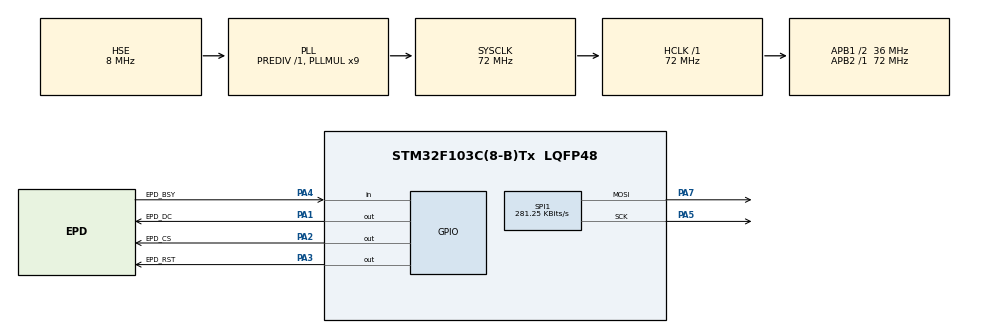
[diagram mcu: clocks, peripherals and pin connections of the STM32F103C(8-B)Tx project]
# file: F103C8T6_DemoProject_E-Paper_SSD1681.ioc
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Dma.Request0=SPI1_TX
Dma.SPI1_TX.0.Direction=DMA_MEMORY_TO_PERIPH
Dma.SPI1_TX.0.Instance=DMA1_Channel3
Dma.SPI1_TX.0.MemDataAlignment=DMA_MDATAALIGN_BYTE
Dma.SPI1_TX.0.MemInc=DMA_MINC_ENABLE
Dma.SPI1_TX.0.Mode=DMA_NORMAL
Dma.SPI1_TX.0.PeriphDataAlignment=DMA_PDATAALIGN_BYTE
Dma.SPI1_TX.0.PeriphInc=DMA_PINC_DISABLE
Dma.SPI1_TX.0.Priority=DMA_PRIORITY_LOW
Mcu.Family=STM32F1
Mcu.Name=STM32F103C(8-B)Tx
Mcu.Package=LQFP48
NVIC.DMA1_Channel3_IRQn=true\:0\:0\:false\:false\:true\:false\:true\:true
NVIC.PriorityGroup=NVIC_PRIORITYGROUP_4
NVIC.SPI1_IRQn=true\:0\:0\:false\:false\:true\:true\:true\:true
PA1.GPIO_Label=EPD_DC
PA1.Signal=GPIO_Output
PA13.Mode=Serial_Wire
PA13.Signal=SYS_JTMS-SWDIO
PA14.Mode=Serial_Wire
PA14.Signal=SYS_JTCK-SWCLK
PA2.GPIO_Label=EPD_CS
PA2.Signal=GPIO_Output
PA3.GPIO_Label=EPD_RST
PA3.Signal=GPIO_Output
PA4.GPIO_Label=EPD_BSY
PA4.Signal=GPIO_Input
PA5.Mode=TX_Only_Simplex_Unidirect_Master
PA5.Signal=SPI1_SCK
PA7.Mode=TX_Only_Simplex_Unidirect_Master
PA7.Signal=SPI1_MOSI
PD0-OSC_IN.Mode=HSE-External-Oscillator
PD0-OSC_IN.Signal=RCC_OSC_IN
PD1-OSC_OUT.Mode=HSE-External-Oscillator
PD1-OSC_OUT.Signal=RCC_OSC_OUT
ProjectManager.HeapSize=0x200
ProjectManager.StackSize=0x400
ProjectManager.TargetToolchain=STM32CubeIDE
RCC.AHBFreq_Value=72000000
RCC.APB1CLKDivider=RCC_HCLK_DIV2
RCC.APB1Freq_Value=36000000
RCC.APB1TimFreq_Value=72000000
RCC.APB2Freq_Value=72000000
RCC.APB2TimFreq_Value=72000000
RCC.HCLKFreq_Value=72000000
RCC.PLLMUL=RCC_PLL_MUL9
RCC.PLLSourceVirtual=RCC_PLLSOURCE_HSE
RCC.SYSCLKFreq_VALUE=72000000
RCC.SYSCLKSource=RCC_SYSCLKSOURCE_PLLCLK
RCC.USBFreq_Value=72000000
SPI1.BaudRatePrescaler=SPI_BAUDRATEPRESCALER_256
SPI1.CLKPhase=SPI_PHASE_1EDGE
SPI1.CLKPolarity=SPI_POLARITY_LOW
SPI1.CalculateBaudRate=281.25 KBits/s
SPI1.Direction=SPI_DIRECTION_2LINES
SPI1.Mode=SPI_MODE_MASTER
SPI1.VirtualType=VM_MASTER
board=custom

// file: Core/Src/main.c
/* USER CODE BEGIN Header */
/**
  ******************************************************************************
  * @file           : main.c
  * @brief          : Main program body
  ******************************************************************************
  * @attention
  *
  * Copyright (c) 2024 STMicroelectronics.
  * All rights reserved.
  *
  * This software is licensed under terms that can be found in the LICENSE file
  * in the root directory of this software component.
  * If no LICENSE file comes with this software, it is provided AS-IS.
  *
  ******************************************************************************
  */
/* USER CODE END Header */
#include "main.h"
#include "EPD_1-54inch.h"

SPI_HandleTypeDef hspi1;
DMA_HandleTypeDef hdma_spi1_tx;

/* USER CODE BEGIN PV */
EPD_StructTd Display;
/* USER CODE END PV */

void SystemClock_Config(void);
static void MX_GPIO_Init(void);
static void MX_DMA_Init(void);
static void MX_SPI1_Init(void);

/* USER CODE BEGIN 0 */
uint8_t mdw_Logo[] = {
		0xFF, 0xFF, 0xFF, 0xFF, 0xFF, 0xFF, 0xFF, 0xFF, 0xFF, 0xFF, 0xFF, 0xFF, 0xFF, 0xFF, 0xFF, 0xFF,
		0xFF, 0xFF, 0xFF, 0xFF, 0xFF, 0xFF, 0xFF, 0xFF, 0xFF, 0xFF, 0xFF, 0xFF, 0xFF, 0xFF, 0xFF, 0xFF,
		0xFF, 0xFF, 0xFF, 0xFF, 0xFF, 0xFF, 0xFF, 0xFF, 0xFF, 0xFF, 0xFF, 0xFF, 0xFF, 0xFF, 0xFF, 0xFF,
		0xFF, 0xFF, 0xFF, 0xFF, 0xFF, 0xFF, 0xFF, 0xFF, 0xFF, 0xFF, 0xFF, 0xFF, 0xFF, 0xFF, 0xFF, 0xFF,
		0xFF, 0xFF, 0xFF, 0xFF, 0xFF, 0xFF, 0xFF, 0xFF, 0xFF, 0xFF, 0xFF, 0xFF, 0xFF, 0xFF, 0xFF, 0xFF,
		0xFF, 0xFF, 0xFF, 0xFF, 0xFF, 0xFF, 0xFF, 0xFF, 0xFF, 0xFF, 0xFF, 0xFF, 0xFF, 0xFF, 0xFF, 0xFF,
		0xFF, 0xFF, 0xFF, 0xFF, 0xFF, 0xFF, 0xFF, 0xFF, 0xFF, 0xFF, 0xFF, 0xFF, 0xFF, 0xFF, 0xFF, 0xFF,
		0xFF, 0xFF, 0xFF, 0xFF, 0xFF, 0xFF, 0xFF, 0xFF, 0xFF, 0xFF, 0xFF, 0xFF, 0xFF, 0xFF, 0xFF, 0xFF,
		0xFF, 0xFF, 0xFF, 0xFF, 0xFF, 0xFF, 0xFF, 0xFF, 0xFF, 0xFF, 0xFF, 0xFF, 0xFF, 0xFF, 0xFF, 0xFF,
		0xFF, 0xFF, 0xFF, 0xFF, 0xFF, 0xFF, 0xFF, 0xFF, 0xFF, 0xFF, 0xFF, 0xFF, 0xFF, 0xFF, 0xFF, 0xFF,
		0xFF, 0xFF, 0xFF, 0xFF, 0xFF, 0xFF, 0xFF, 0xFF, 0xFF, 0xFF, 0xFF, 0xFF, 0xFF, 0xFF, 0xFF, 0xFF,
		0xFF, 0xFF, 0xFF, 0xFF, 0xFF, 0xFF, 0xFF, 0xFF, 0xFF, 0xFF, 0xFF, 0xFF, 0xFF, 0xFF, 0xFF, 0xFF,
		0xFF, 0xFF, 0xFF, 0xFF, 0xFF, 0xFF, 0xFF, 0xFF, 0xFF, 0xFF, 0xFF, 0xFF, 0xFF, 0xFF, 0xFF, 0xFF,
		0xFF, 0xFF, 0xFF, 0xFF, 0xFF, 0xFF, 0xFF, 0xFF, 0xFF, 0xFF, 0xFF, 0xFF, 0xFF, 0xFF, 0xFF, 0xFF,
		0xFF, 0xFF, 0xFF, 0xFF, 0xFF, 0xFF, 0xFF, 0xFF, 0xFF, 0xFF, 0xFF, 0xFF, 0xFF, 0xFF, 0xFF, 0xFF,
		0xFF, 0xFF, 0xFF, 0xFF, 0xFF, 0xFF, 0xFF, 0xFF, 0xFF, 0xFF, 0xFF, 0xFF, 0xFF, 0xFF, 0xFF, 0xFF,
		0xFF, 0xFF, 0xFF, 0xFF, 0xFF, 0xFF, 0xFF, 0xFF, 0xFF, 0xFF, 0xFF, 0xFF, 0xFF, 0xFF, 0xFF, 0xFF,
		0xFF, 0xFF, 0xFF, 0xFF, 0xFF, 0xFF, 0xFF, 0xFF, 0xFF, 0xFF, 0xFF, 0xFF, 0xFF, 0xFF, 0xFF, 0xFF,
		0xFF, 0xFF, 0xFF, 0xFF, 0xFF, 0xFF, 0xFF, 0xFF, 0xFF, 0xFF, 0xFF, 0xFF, 0xFF, 0xFF, 0xFF, 0xFF,
		0xFF, 0xFF, 0xFF, 0xFF, 0xFF, 0xFF, 0xFF, 0xFF, 0xFF, 0xFF, 0xFF, 0xFF, 0xFF, 0xFF, 0xFF, 0xFF,
		0xFF, 0xFF, 0xFF, 0xFF, 0xFF, 0xFF, 0xFF, 0xFF, 0xFF, 0xFF, 0xFF, 0xFF, 0xFF, 0xFF, 0xFF, 0xFF,
		0xFF, 0xFF, 0xFF, 0xFF, 0xFF, 0xFF, 0xFF, 0xFF, 0xFF, 0xFF, 0xFF, 0xFF, 0xFF, 0xFF, 0xFF, 0xFF,
		0xFF, 0xFF, 0xFF, 0xFF, 0xFF, 0xFF, 0xFF, 0xFF, 0xFF, 0xFF, 0xFF, 0xFF, 0xFF, 0xFF, 0xFF, 0xFF,
		0xFF, 0xFF, 0xFF, 0xFF, 0xFF, 0xFF, 0xFF, 0xFF, 0xFF, 0xFF, 0xFF, 0xFF, 0xFF, 0xFF, 0xFF, 0xFF,
		0xFF, 0xFF, 0xFF, 0xFF, 0xFF, 0xFF, 0xFF, 0xFF, 0xFF, 0xFF, 0xFF, 0xFF, 0xFF, 0xFF, 0xFF, 0xFF,
		0xFF, 0xFF, 0xFF, 0xFF, 0xFF, 0xFF, 0xFF, 0xFF, 0xFF, 0xFF, 0xFF, 0xFF, 0xFF, 0xFF, 0xFF, 0xFF,
		0xFF, 0xFF, 0xFF, 0xFF, 0xFF, 0xFF, 0xFF, 0xFF, 0xFF, 0xFF, 0xFF, 0xFF, 0xFF, 0xFF, 0xFF, 0xFF,
		0xFF, 0xFF, 0xFF, 0xFF, 0xFF, 0xFF, 0xFF, 0xFF, 0xFF, 0xFF, 0xFF, 0xFF, 0xFF, 0xFF, 0xFF, 0xFF,
		0xFF, 0xFF, 0xFF, 0xFF, 0xFF, 0xFF, 0xFF, 0xFF, 0xFF, 0xFF, 0xFF, 0xFF, 0xFF, 0xFF, 0xFF, 0xFF,
		0xFF, 0xFF, 0xFF, 0xFF, 0xFF, 0xFF, 0xFF, 0xFF, 0xFF, 0xFF, 0xFF, 0xFF, 0xFF, 0xFF, 0xFF, 0xFF,
		0xFF, 0xFF, 0xFF, 0xFF, 0xFF, 0xFF, 0xFF, 0xFF, 0xFF, 0xFF, 0xFF, 0xFF, 0xFF, 0xFF, 0xFF, 0xFF,
		0xFF, 0xFF, 0xFF, 0xFF, 0xFF, 0xFF, 0xFF, 0xFF, 0xFF, 0xFF, 0xFF, 0xFF, 0xFF, 0xFF, 0xFF, 0xFF,
		0xFF, 0xFF, 0xFF, 0xFF, 0xFF, 0xFF, 0xFF, 0xFF, 0xFF, 0xFF, 0xFF, 0xFF, 0xFF, 0xFF, 0xFF, 0xFF,
		0xFF, 0xFF, 0xFF, 0xFF, 0xFF, 0xFF, 0xFF, 0xFF, 0xFF, 0xFF, 0xFF, 0xFF, 0xFF, 0xFF, 0xFF, 0xFF,
		0xFF, 0xFF, 0xFF, 0xFF, 0xFF, 0xFF, 0xFF, 0xFF, 0xFF, 0xFF, 0xFF, 0xFF, 0xFF, 0xFF, 0xFF, 0xFF,
		0xFF, 0xFF, 0xFF, 0xFF, 0xFF, 0xFF, 0xFF, 0xFF, 0xFF, 0xFF, 0xFF, 0xFF, 0xFF, 0xFF, 0xFF, 0xFF,
		0xFF, 0xFF, 0x0F, 0xFF, 0xFF, 0xC0, 0xFF, 0xFF, 0xFF, 0xFF, 0xFF, 0xFF, 0xFF, 0xFF, 0xFF, 0xFF,
		0xFF, 0xFF, 0xFF, 0xFF, 0xFF, 0xFF, 0xFF, 0xFF, 0xF0, 0x07, 0xF0, 0x00, 0xFF, 0xFE, 0x00, 0x0F,
		0xFF, 0xFF, 0xFF, 0xFF, 0xFF, 0xFF, 0xFF, 0xFF, 0xFF, 0xFF, 0xFF, 0xFF, 0xFF, 0xFF, 0xFF, 0xFF,
		0xFF, 0xE0, 0x03, 0xC0, 0x00, 0x3F, 0xF0, 0x00, 0x03, 0xFF, 0xFF, 0xFF, 0xFF, 0xFF, 0xFF, 0xFF,
		0xFF, 0xFF, 0xFF, 0xFF, 0xFF, 0xFF, 0xFF, 0xFF, 0xFF, 0xFF, 0xE0, 0x03, 0x80, 0x00, 0x1F, 0xE0,
		0x00, 0x01, 0xFF, 0xFF, 0xFF, 0xFF, 0xFF, 0xFF, 0xFF, 0xFF, 0xFF, 0xFF, 0xFF, 0xFF, 0xFF, 0xFF,
		0xFF, 0xFF, 0xFF, 0xE0, 0x03, 0x00, 0x00, 0x0F, 0x80, 0x00, 0x00, 0x7F, 0xFF, 0xFF, 0xFF, 0xFF,
		0xFF, 0xFF, 0xFF, 0xFF, 0xFF, 0xFF, 0xFF, 0xFF, 0xFF, 0xFF, 0xFF, 0xFF, 0xE0, 0x02, 0x00, 0x00,
		0x07, 0x00, 0x00, 0x00, 0x7F, 0xFF, 0xFF, 0xFF, 0xFF, 0xFF, 0xFF, 0xFF, 0xFF, 0xFF, 0xFF, 0xFF,
		0xFF, 0xFF, 0xFF, 0xFF, 0xFF, 0xE0, 0x00, 0x00, 0x00, 0x02, 0x00, 0x00, 0x00, 0x3F, 0xFF, 0xFF,
		0xFF, 0xFF, 0xFF, 0xFF, 0xFF, 0xFF, 0xFF, 0xFF, 0xFF, 0xFF, 0xFF, 0xFF, 0xFF, 0xFF, 0xE0, 0x00,
		0x00, 0x00, 0x00, 0x00, 0x00, 0x00, 0x1F, 0xFF, 0xFF, 0xFF, 0xFF, 0xFF, 0xFF, 0xFF, 0xFF, 0xFF,
		0xFF, 0xFF, 0xFF, 0xFF, 0xFF, 0xFF, 0xFF, 0xE0, 0x00, 0x00, 0x00, 0x00, 0x00, 0x00, 0x00, 0x1F,
		0xFF, 0xFF, 0xFF, 0xFF, 0xFF, 0xFF, 0xFF, 0xFF, 0xFF, 0xFF, 0xFF, 0xFF, 0xFF, 0xFF, 0xFF, 0xFF,
		0xE0, 0x00, 0x00, 0x00, 0x00, 0x00, 0x00, 0x00, 0x0F, 0xFF, 0xFF, 0xFF, 0xFF, 0xFF, 0xFF, 0xFF,
		0xFF, 0xFF, 0xFF, 0xFF, 0xFF, 0xFF, 0xFF, 0xFF, 0xFF, 0xE0, 0x00, 0x00, 0x00, 0x00, 0x00, 0x00,
		0x00, 0x0F, 0xFF, 0xFF, 0xFF, 0xFF, 0xFF, 0xFF, 0xFF, 0xFF, 0xFF, 0xFF, 0xFF, 0xFF, 0xFF, 0xFF,
		0xFF, 0xFF, 0xE0, 0x00, 0x00, 0x00, 0x00, 0x00, 0x00, 0x00, 0x0F, 0xFF, 0xFF, 0xFF, 0xFF, 0xFF,
		0xFF, 0xFF, 0xFF, 0xFF, 0xFF, 0xFF, 0xFF, 0xFF, 0xFF, 0xFF, 0xFF, 0xE0, 0x00, 0x00, 0x00, 0x00,
		0x01, 0xF0, 0x00, 0x07, 0xFF, 0xFF, 0xFF, 0xFF, 0xFF, 0xFF, 0xFF, 0xFF, 0xFF, 0xFF, 0xFF, 0xFF,
		0xFF, 0xFF, 0xFF, 0xFF, 0xE0, 0x00, 0x0F, 0xC0, 0x00, 0x07, 0xF8, 0x00, 0x07, 0xFF, 0xFF, 0xFF,
		0xFF, 0xFF, 0xFF, 0xFF, 0xFF, 0xFF, 0xFF, 0xFF, 0xFF, 0xFF, 0xFF, 0xFF, 0xFF, 0xE0, 0x00, 0x3F,
		0xE0, 0x00, 0x0F, 0xFC, 0x00, 0x07, 0xFF, 0xFF, 0xFF, 0xFF, 0xFF, 0xFF, 0xFF, 0xFF, 0xFF, 0xFF,
		0xFF, 0xFF, 0xFF, 0xFF, 0xFF, 0xFF, 0xE0, 0x00, 0x7F, 0xF0, 0x00, 0x1F, 0xFE, 0x00, 0x07, 0xFF,
		0xFF, 0xFF, 0xFF, 0xFF, 0xFF, 0xFF, 0xFF, 0xFF, 0xFF, 0xFF, 0xFF, 0xFF, 0xFF, 0xFF, 0xFF, 0xE0,
		0x00, 0xFF, 0xF8, 0x00, 0x1F, 0xFF, 0x00, 0x07, 0xFF, 0xFF, 0xFF, 0xFF, 0xFF, 0xFF, 0xFF, 0xFF,
		0xFF, 0xFF, 0xFF, 0xFF, 0xFF, 0xFF, 0xFF, 0xFF, 0xE0, 0x00, 0xFF, 0xF8, 0x00, 0x1F, 0xFF, 0x00,
		0x07, 0xFF, 0xFF, 0xFF, 0xFF, 0xFF, 0xFF, 0xFF, 0xFF, 0xFF, 0xFF, 0xFF, 0xFF, 0xFF, 0xFF, 0xFF,
		0xFF, 0xE0, 0x00, 0xFF, 0xF8, 0x00, 0x3F, 0xFF, 0x00, 0x07, 0xFF, 0xFF, 0xFF, 0xFF, 0xFF, 0xFF,
		0xFF, 0xFF, 0xFF, 0xFF, 0xFF, 0xFF, 0xFF, 0xFF, 0xFF, 0xFF, 0xE0, 0x01, 0xFF, 0xF8, 0x00, 0x3F,
		0xFF, 0x00, 0x07, 0xFF, 0xFF, 0xFF, 0xFF, 0xFF, 0xFF, 0xFF, 0xFF, 0xFF, 0xFF, 0xFF, 0xFF, 0xFF,
		0xFF, 0xFF, 0xFF, 0xE0, 0x01, 0xFF, 0xF8, 0x00, 0x3F, 0xFF, 0x00, 0x07, 0xFF, 0xFF, 0xFF, 0xFF,
		0xFF, 0xFF, 0xFF, 0xFF, 0xFF, 0xFF, 0xFF, 0xFF, 0xFF, 0xFF, 0xFF, 0xFF, 0xE0, 0x01, 0xFF, 0xF8,
		0x00, 0x3F, 0xFF, 0x00, 0x07, 0xFF, 0xFF, 0xFF, 0xFF, 0xFF, 0xFF, 0xFF, 0xFF, 0xFF, 0xFF, 0xFF,
		0xFF, 0xFF, 0xFF, 0xFF, 0xFF, 0xE0, 0x01, 0xFF, 0xF8, 0x00, 0x3F, 0xFF, 0x00, 0x07, 0xFF, 0xFF,
		0xFF, 0xFF, 0xFF, 0xFF, 0xFF, 0xFF, 0xFF, 0xFF, 0xFF, 0xFF, 0xFF, 0xFF, 0xFF, 0xFF, 0xE0, 0x01,
		0xFF, 0xF8, 0x00, 0x3F, 0xFF, 0x00, 0x07, 0xFF, 0xFF, 0xFF, 0xFF, 0xFF, 0xFF, 0xFF, 0xFF, 0xFF,
		0xFF, 0xFF, 0xFF, 0xFF, 0xFF, 0xFF, 0xFF, 0xE0, 0x01, 0xFF, 0xF8, 0x00, 0x3F, 0xFF, 0x00, 0x07,
		0xFF, 0xFF, 0xFF, 0xFF, 0xFF, 0xFF, 0xFF, 0xFF, 0xFF, 0xFF, 0xFF, 0xFF, 0xFF, 0xFF, 0xFF, 0xFF,
		0xE0, 0x01, 0xFF, 0xF8, 0x00, 0x3F, 0xFF, 0x00, 0x07, 0xFF, 0xFF, 0xFF, 0xFF, 0xFF, 0xFF, 0xFF,
		0xFF, 0xFF, 0xFF, 0xFF, 0xFF, 0xFF, 0xFF, 0xFF, 0xFF, 0xE0, 0x01, 0xFF, 0xF8, 0x00, 0x3F, 0xFF,
		0x00, 0x07, 0xFF, 0xFF, 0xFF, 0xFF, 0xFF, 0xFF, 0xFF, 0xFF, 0xFF, 0xFF, 0xFF, 0xFF, 0xFF, 0xFF,
		0xFF, 0xFF, 0xE0, 0x01, 0xFF, 0xF8, 0x00, 0x3F, 0xFF, 0x00, 0x07, 0x80, 0x03, 0xFF, 0xF0, 0x01,
		0xFF, 0xFC, 0x00, 0x1F, 0xFF, 0xFF, 0xFF, 0xFF, 0xFF, 0xFF, 0xFF, 0xE0, 0x01, 0xFF, 0xF8, 0x00,
		0x3F, 0xFF, 0x00, 0x07, 0x80, 0x03, 0xFF, 0xF0, 0x00, 0xFF, 0xFC, 0x00, 0x1F, 0xFF, 0xFF, 0xFF,
		0xFF, 0xFF, 0xFF, 0xFF, 0xE0, 0x01, 0xFF, 0xF8, 0x00, 0x3F, 0xFF, 0x00, 0x07, 0xC0, 0x01, 0xFF,
		0xF0, 0x00, 0xFF, 0xF8, 0x00, 0x3F, 0xFF, 0xFF, 0xFF, 0xFF, 0xFF, 0xFF, 0xFF, 0xE0, 0x01, 0xFF,
		0xF8, 0x00, 0x3F, 0xFF, 0x00, 0x07, 0xC0, 0x01, 0xFF, 0xE0, 0x00, 0xFF, 0xF8, 0x00, 0x3F, 0xFF,
		0xFF, 0xFF, 0xFF, 0xFF, 0xFF, 0xFF, 0xE0, 0x01, 0xFF, 0xF8, 0x00, 0x3F, 0xFF, 0x00, 0x07, 0xC0,
		0x01, 0xFF, 0xE0, 0x00, 0x7F, 0xF8, 0x00, 0x3F, 0xFF, 0xFF, 0xFF, 0xFF, 0xFF, 0xFF, 0xFF, 0xE0,
		0x01, 0xFF, 0xF8, 0x00, 0x3F, 0xFF, 0x00, 0x07, 0xE0, 0x01, 0xFF, 0xE0, 0x00, 0x7F, 0xF0, 0x00,
		0x7F, 0xFF, 0xFF, 0xFF, 0xFF, 0xFF, 0xFF, 0xFF, 0xE0, 0x01, 0xFF, 0xF8, 0x00, 0x3F, 0xFF, 0x00,
		0x07, 0xE0, 0x00, 0xFF, 0xC0, 0x00, 0x7F, 0xF0, 0x00, 0x7F, 0xFF, 0xFF, 0xFF, 0xFF, 0xFF, 0xFF,
		0xFF, 0xE0, 0x01, 0xFF, 0xF8, 0x00, 0x3F, 0xFF, 0x00, 0x07, 0xE0, 0x00, 0xFF, 0xC0, 0x00, 0x3F,
		0xF0, 0x00, 0x7F, 0xFF, 0xFF, 0xFF, 0xFF, 0xFF, 0xFF, 0xFF, 0xE0, 0x01, 0xFF, 0xF8, 0x00, 0x3F,
		0xFF, 0x00, 0x07, 0xE0, 0x00, 0xFF, 0xC0, 0x00, 0x3F, 0xE0, 0x00, 0xFF, 0xFF, 0xFF, 0xFF, 0xFF,
		0xFF, 0xFF, 0xFF, 0xE0, 0x01, 0xFF, 0xF8, 0x00, 0x3F, 0xFF, 0x00, 0x07, 0xF0, 0x00, 0xFF, 0x80,
		0x00, 0x3F, 0xE0, 0x00, 0xFF, 0xFF, 0xFF, 0xFF, 0xFF, 0xFF, 0xFF, 0xFF, 0xE0, 0x01, 0xFF, 0xF8,
		0x00, 0x3F, 0xFF, 0x00, 0x07, 0xF0, 0x00, 0x7F, 0x80, 0x00, 0x3F, 0xE0, 0x00, 0xFF, 0xFF, 0xFF,
		0xFF, 0xFF, 0xFF, 0xFF, 0xFF, 0xE0, 0x01, 0xFF, 0xF8, 0x00, 0x3F, 0xFF, 0x00, 0x07, 0xF0, 0x00,
		0x7F, 0x80, 0x00, 0x1F, 0xC0, 0x01, 0xFF, 0xFF, 0xFF, 0xFF, 0xFF, 0xFF, 0xFF, 0xFF, 0xE0, 0x01,
		0xFF, 0xF8, 0x00, 0x3F, 0xFF, 0x00, 0x07, 0xF0, 0x00, 0x7F, 0x80, 0x00, 0x1F, 0xC0, 0x01, 0xFF,
		0xFF, 0xFF, 0xFF, 0xFF, 0xFF, 0xFF, 0xFF, 0xE0, 0x01, 0xFF, 0xF8, 0x00, 0x3F, 0xFF, 0x00, 0x07,
		0xF8, 0x00, 0x7F, 0x00, 0x00, 0x1F, 0xC0, 0x01, 0xFF, 0xFF, 0xFF, 0xFF, 0xFF, 0xFF, 0xFF, 0xFF,
		0xE0, 0x01, 0xFF, 0xF8, 0x00, 0x3F, 0xFF, 0x00, 0x07, 0xF8, 0x00, 0x3F, 0x00, 0x00, 0x1F, 0xC0,
		0x03, 0xFF, 0xFF, 0xFF, 0xFF, 0xFF, 0xFF, 0xFF, 0xFF, 0xE0, 0x01, 0xFF, 0xF8, 0x00, 0x3F, 0xFF,
		0x00, 0x07, 0xF8, 0x00, 0x3E, 0x00, 0x00, 0x0F, 0x80, 0x03, 0xFF, 0xFF, 0xFF, 0xFF, 0xFF, 0xFF,
		0xFF, 0xFF, 0xE0, 0x01, 0xFF, 0xF8, 0x00, 0x3F, 0xFF, 0x00, 0x07, 0xFC, 0x00, 0x3E, 0x00, 0x00,
		0x0F, 0x80, 0x07, 0xFF, 0xFF, 0xFF, 0xFF, 0xFF, 0xFF, 0xFF, 0xFF, 0xE0, 0x01, 0xFF, 0xF8, 0x00,
		0x3F, 0xFF, 0x00, 0x07, 0xFC, 0x00, 0x1E, 0x00, 0x00, 0x0F, 0x80, 0x07, 0xFF, 0xFF, 0xFF, 0xFF,
		0xFF, 0xFF, 0xFF, 0xFF, 0xFF, 0xFF, 0xFF, 0xFF, 0xFF, 0xFF, 0xFF, 0x00, 0x07, 0xFC, 0x00, 0x1E,
		0x00, 0x00, 0x07, 0x00, 0x07, 0xFF, 0xFF, 0xFF, 0xFF, 0xFF, 0xFF, 0xFF, 0xFF, 0xFF, 0xFF, 0xFF,
		0xFF, 0xFF, 0xFF, 0xFF, 0x00, 0x07, 0xFC, 0x00, 0x1C, 0x00, 0x00, 0x07, 0x00, 0x07, 0xFF, 0xFF,
		0xFF, 0xFF, 0xFF, 0xFF, 0xFF, 0xFF, 0xFF, 0xFF, 0xFF, 0xFF, 0xFF, 0xFF, 0xFF, 0x00, 0x07, 0xFE,
		0x00, 0x1C, 0x00, 0x00, 0x07, 0x00, 0x0F, 0xFF, 0xFF, 0xFF, 0xFF, 0xFF, 0xFF, 0xFF, 0xFF, 0xFF,
		0xFF, 0xFF, 0xFF, 0xFF, 0xFF, 0xFF, 0x00, 0x07, 0xFE, 0x00, 0x1C, 0x00, 0x00, 0x06, 0x00, 0x0F,
		0xFF, 0xFF, 0xFF, 0xFF, 0xFF, 0xFF, 0xFF, 0xFF, 0xFF, 0xFF, 0xFF, 0xFF, 0xFF, 0xFF, 0xFF, 0x00,
		0x07, 0xFE, 0x00, 0x0C, 0x00, 0x40, 0x02, 0x00, 0x0F, 0xFF, 0xFF, 0xFF, 0xFF, 0xFF, 0xFF, 0xFF,
		0xFF, 0xFF, 0xFF, 0xFF, 0xFF, 0xFF, 0xFF, 0xFF, 0x00, 0x07, 0xFE, 0x00, 0x08, 0x00, 0xC0, 0x02,
		0x00, 0x1F, 0xFF, 0xFF, 0xFF, 0xFF, 0xFF, 0xFF, 0xFF, 0xFF, 0xFF, 0xFF, 0xFF, 0xFF, 0xFF, 0xFF,
		0xFF, 0x00, 0x07, 0xFF, 0x00, 0x00, 0x00, 0xC0, 0x00, 0x00, 0x1F, 0xFF, 0xFF, 0xFF, 0xFF, 0xFF,
		0xFF, 0xFF, 0xFF, 0xFF, 0xFF, 0xFF, 0xFF, 0xFF, 0xFF, 0xFF, 0x00, 0x07, 0xFF, 0x00, 0x00, 0x00,
		0xE0, 0x00, 0x00, 0x1F, 0xFF, 0xFF, 0xFF, 0xFF, 0xFF, 0xFF, 0xFF, 0xFF, 0xFF, 0xFF, 0xFF, 0xFF,
		0xFF, 0xFF, 0xFF, 0x00, 0x07, 0xFF, 0x00, 0x00, 0x01, 0xE0, 0x00, 0x00, 0x3F, 0xFF, 0xFF, 0xFF,
		0xFF, 0xFF, 0xFF, 0xFF, 0xFF, 0xFF, 0xFF, 0xFF, 0xFF, 0xFF, 0xFF, 0xFF, 0x00, 0x07, 0xFF, 0x80,
		0x00, 0x01, 0xE0, 0x00, 0x00, 0x3F, 0xFF, 0xFF, 0xFF, 0xFF, 0xFF, 0xFF, 0xFF, 0xFF, 0xFF, 0xFF,
		0xFF, 0xFF, 0xFF, 0xFF, 0xFF, 0x00, 0x07, 0xFF, 0x80, 0x00, 0x03, 0xE0, 0x00, 0x00, 0x3F, 0xFF,
		0xFF, 0xFF, 0xFF, 0xFF, 0xFF, 0xFF, 0xFF, 0xFF, 0xFF, 0xFF, 0xFF, 0xFF, 0xFF, 0xFF, 0x00, 0x07,
		0xFF, 0x80, 0x00, 0x03, 0xF0, 0x00, 0x00, 0x7F, 0xFF, 0xFF, 0xFF, 0xFF, 0xFF, 0xFF, 0xFF, 0xFF,
		0xFF, 0xFF, 0xFF, 0xFF, 0xFF, 0xFF, 0xFF, 0x00, 0x07, 0xFF, 0x80, 0x00, 0x03, 0xF0, 0x00, 0x00,
		0x7F, 0xFF, 0xFF, 0xFF, 0xFF, 0xFF, 0xFF, 0xFF, 0xFF, 0xFF, 0xFF, 0xFF, 0xFF, 0xFF, 0xFF, 0xFF,
		0x00, 0x07, 0xFF, 0xC0, 0x00, 0x07, 0xF0, 0x00, 0x00, 0x7F, 0xFF, 0xFF, 0xFF, 0xFF, 0xFF, 0xFF,
		0xFF, 0xFF, 0xFF, 0xFF, 0xFF, 0xFF, 0xFF, 0xFF, 0xFF, 0x00, 0x07, 0xFF, 0xC0, 0x00, 0x07, 0xF8,
		0x00, 0x00, 0xFF, 0xFF, 0xFF, 0xFF, 0xFF, 0xFF, 0xFF, 0xFF, 0xFF, 0xFF, 0xFF, 0xFF, 0xFF, 0xFF,
		0xFF, 0xFF, 0x00, 0x07, 0xFF, 0xC0, 0x00, 0x07, 0xF8, 0x00, 0x00, 0xFF, 0xFF, 0xFF, 0xFF, 0xFF,
		0xFF, 0xFF, 0xFF, 0xFF, 0xFF, 0xFF, 0xFF, 0xFF, 0xFF, 0x80, 0x7F, 0x00, 0x07, 0xFF, 0xE0, 0x00,
		0x0F, 0xF8, 0x00, 0x00, 0xFF, 0xFF, 0xFF, 0xFF, 0xFF, 0xFF, 0xFF, 0xFF, 0xFF, 0xFF, 0xFF, 0xFF,
		0xFF, 0xF8, 0x00, 0x07, 0x00, 0x07, 0xFF, 0xE0, 0x00, 0x0F, 0xF8, 0x00, 0x01, 0xFF, 0xFF, 0xFF,
		0xFF, 0xFF, 0xFF, 0xFF, 0xFF, 0xFF, 0xFF, 0xFF, 0xFF, 0xFF, 0xE0, 0x00, 0x03, 0x00, 0x07, 0xFF,
		0xE0, 0x00, 0x0F, 0xFC, 0x00, 0x01, 0xFF, 0xFF, 0xFF, 0xFF, 0xFF, 0xFF, 0xFF, 0xFF, 0xFF, 0xFF,
		0xFF, 0xFF, 0xFF, 0x80, 0x00, 0x0F, 0x00, 0x07, 0xFF, 0xE0, 0x00, 0x1F, 0xFC, 0x00, 0x01, 0xFF,
		0xFF, 0xFF, 0xFF, 0xFF, 0xFF, 0xFF, 0xFF, 0xFF, 0xFF, 0xFF, 0xFF, 0xFF, 0x00, 0x00, 0x7F, 0x00,
		0x07, 0xFF, 0xF0, 0x00, 0x1F, 0xFC, 0x00, 0x03, 0xFF, 0xFF, 0xFF, 0xFF, 0xFF, 0xFF, 0xFF, 0xFF,
		0xFF, 0xFF, 0xFF, 0xFF, 0xFE, 0x00, 0x01, 0xFF, 0x00, 0x07, 0xFF, 0xF0, 0x00, 0x1F, 0xFE, 0x00,
		0x03, 0xFF, 0xFF, 0xFF, 0xFF, 0xFF, 0xFF, 0xFF, 0xFF, 0xFF, 0xFF, 0xFF, 0xFF, 0xFC, 0x00, 0x07,
		0xFF, 0x00, 0x07, 0xFF, 0xF0, 0x00, 0x3F, 0xFE, 0x00, 0x07, 0xFF, 0xFF, 0xFF, 0xFF, 0xFF, 0xFF,
		0xFF, 0xFF, 0xFF, 0xFF, 0xFF, 0xFF, 0xF8, 0x00, 0x1F, 0xFF, 0x00, 0x07, 0xFF, 0xF0, 0x00, 0x3F,
		0xFE, 0x00, 0x07, 0xFF, 0xFF, 0xFF, 0xFF, 0xFF, 0xFF, 0xFF, 0xFF, 0xFF, 0xFF, 0xFF, 0xFF, 0xF0,
		0x00, 0x3F, 0xFF, 0x00, 0x07, 0xFF, 0xF8, 0x00, 0x3F, 0xFF, 0x00, 0x07, 0xFF, 0xFF, 0xFF, 0xFF,
		0xFF, 0xFF, 0xFF, 0xFF, 0xFF, 0xFF, 0xFF, 0xFF, 0xF0, 0x00, 0x00, 0x00, 0x00, 0x07, 0xFF, 0xF8,
		0x00, 0x7F, 0xFF, 0x00, 0x0F, 0xFF, 0xFF, 0xFF, 0xFF, 0xFF, 0xFF, 0xFF, 0xFF, 0xFF, 0xFF, 0xFF,
		0xFF, 0xE0, 0x00, 0x00, 0x00, 0x00, 0x07, 0xFF, 0xFF, 0xFF, 0xFF, 0xFF, 0xFF, 0xFF, 0xFF, 0xFF,
		0xFF, 0xFF, 0xFF, 0xFF, 0xFF, 0xFF, 0xFF, 0xFF, 0xFF, 0xFF, 0xC0, 0x00, 0xFF, 0xFF, 0x00, 0x07,
		0xFF, 0xFF, 0xFF, 0xFF, 0xFF, 0xFF, 0xFF, 0xFF, 0xFF, 0xFF, 0xFF, 0xFF, 0xFF, 0xFF, 0xFF, 0xFF,
		0xFF, 0xFF, 0xFF, 0xC0, 0x01, 0xFF, 0xFF, 0x00, 0x07, 0xFF, 0xFF, 0xFF, 0xFF, 0xFF, 0xFF, 0xFF,
		0xFF, 0xFF, 0xFF, 0xFF, 0xFF, 0xFF, 0xFF, 0xFF, 0xFF, 0xFF, 0xFF, 0xFF, 0xC0, 0x01, 0xFF, 0xFE,
		0x00, 0x07, 0xFF, 0xFF, 0xFF, 0xFF, 0xFF, 0xFF, 0xFF, 0xFF, 0xFF, 0xFF, 0xFF, 0xFF, 0xFF, 0xFF,
		0xFF, 0xFF, 0xFF, 0xFF, 0xFF, 0x80, 0x00, 0x00, 0x00, 0x00, 0x07, 0xFF, 0xFF, 0xFF, 0xFF, 0xFF,
		0xFF, 0xFF, 0xFF, 0xFF, 0xFF, 0xFF, 0xFF, 0xFF, 0xFF, 0xFF, 0xFF, 0xFF, 0xFF, 0xFF, 0x80, 0x03,
		0xFF, 0xFE, 0x00, 0x07, 0xFF, 0xFF, 0xFF, 0xFF, 0xFF, 0xFF, 0xFF, 0xFF, 0xFF, 0xFF, 0xFF, 0xFF,
		0xFF, 0xFF, 0xFF, 0xFF, 0xFF, 0xFF, 0xFF, 0x80, 0x07, 0xFF, 0x7F, 0x00, 0x07, 0xFF, 0xFF, 0xFF,
		0xFF, 0xFF, 0xFF, 0xFF, 0xFF, 0xFF, 0xFF, 0xFF, 0xFF, 0xFF, 0xFF, 0xFF, 0xFF, 0xFF, 0xFF, 0xFF,
		0x00, 0x07, 0xF8, 0x0F, 0x00, 0x07, 0xFF, 0xFF, 0xFF, 0xFF, 0xFF, 0xFF, 0xFF, 0xFF, 0xFF, 0xFF,
		0xFF, 0xFF, 0xFF, 0xFF, 0xFF, 0xFF, 0xFF, 0xFF, 0xFF, 0x00, 0x07, 0xF0, 0x06, 0x00, 0x07, 0xFF,
		0xFF, 0xFF, 0xFF, 0xFF, 0xFF, 0xFF, 0xFF, 0xFF, 0xFF, 0xFF, 0xFF, 0xFF, 0xFF, 0xFF, 0xFF, 0xFF,
		0xFF, 0xFF, 0x00, 0x00, 0x00, 0x00, 0x00, 0x07, 0xFF, 0xFF, 0xFF, 0xFF, 0xFF, 0xFF, 0xFF, 0xFF,
		0xFF, 0xFF, 0xFF, 0xFF, 0xFF, 0xFF, 0xFF, 0xFF, 0xFF, 0xFF, 0xFF, 0x00, 0x0F, 0xF8, 0x0F, 0x00,
		0x07, 0xFF, 0xFF, 0xFF, 0xFF, 0xFF, 0xFF, 0xFF, 0xFF, 0xFF, 0xFF, 0xFF, 0xFF, 0xFF, 0xFF, 0xFF,
		0xFF, 0xFF, 0xFF, 0xFF, 0x00, 0x0F, 0xFE, 0x3F, 0x00, 0x07, 0xFF, 0xFF, 0xFF, 0xFF, 0xFF, 0xFF,
		0xFF, 0xFF, 0xFF, 0xFF, 0xFF, 0xFF, 0xFF, 0xFF, 0xFF, 0xFF, 0xFF, 0xFF, 0xFF, 0x00, 0x0F, 0xFF,
		0xFF, 0x00, 0x07, 0xFF, 0xFF, 0xFF, 0xFF, 0xCF, 0xFF, 0xFF, 0xFF, 0xFF, 0xE7, 0xFE, 0x6F, 0xFF,
		0xFF, 0xFF, 0xFF, 0xFF, 0xFF, 0xFF, 0x00, 0x00, 0x00, 0x00, 0x00, 0x07, 0xFF, 0xFF, 0xFF, 0xFF,
		0xCF, 0xFF, 0xFF, 0xFF, 0xFF, 0xEF, 0xFE, 0xEF, 0xFF, 0xFF, 0xFF, 0xFF, 0xFF, 0xFF, 0xFF, 0x00,
		0x07, 0xFF, 0xFE, 0x00, 0x07, 0xFF, 0xFF, 0xFF, 0xFF, 0xFF, 0xFF, 0xFF, 0xFF, 0xFF, 0xFF, 0x3F,
		0xFF, 0xBF, 0xFF, 0xFF, 0xFF, 0xFF, 0xFF, 0xFF, 0x00, 0x0F, 0xFF, 0xFF, 0x00, 0x07, 0xFF, 0xFF,
		0xFF, 0xFF, 0xFF, 0xFF, 0xFF, 0xFF, 0xFF, 0xFF, 0x3F, 0xFF, 0x1F, 0xFF, 0xFF, 0xFF, 0xFF, 0xFF,
		0xFF, 0x00, 0x0F, 0xFF, 0xFF, 0x00, 0x07, 0xFF, 0xF9, 0xF7, 0x61, 0xCC, 0xF9, 0xC1, 0xEC, 0xC0,
		0xEE, 0x0E, 0x0E, 0x0F, 0xFF, 0xFF, 0xFF, 0xFF, 0xFF, 0xFF, 0x00, 0x07, 0xFF, 0xFE, 0x00, 0x07,
		0xFF, 0xF9, 0xF7, 0x19, 0xCC, 0xF9, 0x9C, 0xE3, 0xCC, 0xEE, 0x3C, 0xE7, 0x1F, 0xFF, 0xFF, 0xFF,
		0xFF, 0xFF, 0xFF, 0x00, 0x00, 0x00, 0x00, 0x00, 0x0F, 0xFF, 0xF9, 0xF7, 0x3C, 0xCE, 0x73, 0x3E,
		0xE7, 0x9F, 0xEF, 0x3F, 0xE7, 0xBF, 0xFF, 0xFF, 0xFF, 0xFF, 0xFF, 0xFF, 0x80, 0x07, 0xFF, 0xFF,
		0x00, 0x0F, 0xFF, 0xF9, 0xF7, 0x7C, 0xCE, 0x73, 0x3C, 0x67, 0xCF, 0xEF, 0x3F, 0xE7, 0xBF, 0xFF,
		0xFF, 0xFF, 0xFF, 0xFF, 0xFF, 0x80, 0x07, 0xFF, 0xFF, 0x00, 0x0F, 0xFF, 0xF9, 0xF7, 0x7C, 0xCE,
		0x77, 0x00, 0xEF, 0xC1, 0xEF, 0x3E, 0x07, 0xBF, 0xFF, 0xFF, 0xFF, 0xFF, 0xFF, 0xFF, 0x80, 0x03,
		0xFF, 0xFC, 0x00, 0x0F, 0xFF, 0xF9, 0xF7, 0x7C, 0xCF, 0x27, 0x3F, 0xEF, 0xF8, 0xEF, 0x3C, 0xE7,
		0xBF, 0xFF, 0xFF, 0xFF, 0xFF, 0xFF, 0xFF, 0xC0, 0x03, 0xFF, 0xF0, 0x00, 0x1F, 0xFF, 0xF9, 0xE7,
		0x7C, 0xCF, 0x07, 0x3F, 0xEF, 0xFE, 0x6F, 0x39, 0xE7, 0x3F, 0xFF, 0xFF, 0xFF, 0xFF, 0xFF, 0xFF,
		0xC0, 0x01, 0xFF, 0xF0, 0x00, 0x1F, 0xFF, 0xF8, 0xE7, 0x7C, 0xCF, 0x8F, 0x9C, 0xEF, 0x9E, 0x6F,
		0x38, 0xE7, 0x9F, 0xFF, 0xFF, 0xFF, 0xFF, 0xFF, 0xFF, 0xE0, 0x01, 0xFF, 0xF0, 0x00, 0x3F, 0xFF,
		0xFC, 0x07, 0x7C, 0xCF, 0x8F, 0x88, 0xEF, 0xC0, 0xEF, 0x1C, 0x07, 0x8F, 0xFF, 0xFF, 0xFF, 0xFF,
		0xFF, 0xFF, 0xE0, 0x00, 0xFF, 0xF8, 0x00, 0x3F, 0xFF, 0xFF, 0xFF, 0xFF, 0xFF, 0xFF, 0xF7, 0xFF,
		0xF3, 0xFF, 0xFF, 0x7F, 0xFF, 0xFF, 0xFF, 0xFF, 0xFF, 0xFF, 0xFF, 0xF0, 0x00, 0x7F, 0xFE, 0x00,
		0x7F, 0xFF, 0xFF, 0xFF, 0xFF, 0xFF, 0xFF, 0xFF, 0xFF, 0xFF, 0xFF, 0xFF, 0xFF, 0xFF, 0xFF, 0xFF,
		0xFF, 0xFF, 0xFF, 0xFF, 0xF8, 0x00, 0x3F, 0xFF, 0x00, 0xFF, 0xFF, 0xFF, 0xFF, 0xFF, 0xFF, 0xFF,
		0xFF, 0xFF, 0xFF, 0xFF, 0xFF, 0xFF, 0xFF, 0xFF, 0xFF, 0xFF, 0xFF, 0xFF, 0xFF, 0xFC, 0x00, 0x1F,
		0xFF, 0x01, 0xFF, 0xFF, 0xFF, 0xFF, 0xFF, 0xFF, 0xFF, 0xFF, 0xFF, 0xFF, 0xFF, 0xFF, 0xFF, 0xFF,
		0xFF, 0xFF, 0xFF, 0xFF, 0xFF, 0xFF, 0xFE, 0x00, 0x0F, 0xFF, 0x03, 0xFF, 0xFF, 0xFF, 0xFF, 0xFF,
		0xFF, 0xFF, 0xFF, 0xFF, 0xFF, 0xFF, 0xFF, 0xFF, 0xFF, 0xFF, 0xFF, 0xFF, 0xFF, 0xFF, 0xFF, 0xFF,
		0x00, 0x03, 0xFF, 0x07, 0xFF, 0xFF, 0xFE, 0x7F, 0xFF, 0xFF, 0xFF, 0xFF, 0xFF, 0xFF, 0xFF, 0xFF,
		0xFF, 0xFF, 0xFF, 0xFF, 0xFF, 0xFF, 0xFF, 0xFF, 0xFF, 0xC0, 0x00, 0xFF, 0x0F, 0xFF, 0xFF, 0xFC,
		0x39, 0xBF, 0xFF, 0xFF, 0xFF, 0xFF, 0xFF, 0xFC, 0xDF, 0xFF, 0xFF, 0xFF, 0xFF, 0xE7, 0xFF, 0xFF,
		0xFF, 0xFF, 0xF0, 0x00, 0x3F, 0x3F, 0xFF, 0xFF, 0xFC, 0xFF, 0xFF, 0xFF, 0xFF, 0xFF, 0xFF, 0xFF,
		0xFF, 0xDF, 0xFF, 0xFF, 0xFF, 0xFF, 0xE7, 0xFF, 0xFF, 0xFF, 0xFF, 0xFC, 0x00, 0x03, 0xFF, 0xFF,
		0xFF, 0xFD, 0xFF, 0xFF, 0xFF, 0xFF, 0xFF, 0xFF, 0xFF, 0xFF, 0xDF, 0xFF, 0xFF, 0xFF, 0xFF, 0xE7,
		0xFF, 0xFF, 0xFF, 0xFF, 0xFF, 0x80, 0x0F, 0xFF, 0xFF, 0xFF, 0xF8, 0xFF, 0xFF, 0xFF, 0xF9, 0xF3,
		0xFF, 0xFE, 0x3F, 0xDF, 0xFF, 0xFF, 0xFC, 0xFE, 0x67, 0xFF, 0xFF, 0xFF, 0xFF, 0xFF, 0xFF, 0xFF,
		0xFF, 0xFF, 0xFF, 0xF0, 0x77, 0xCC, 0x1F, 0xC0, 0x41, 0xCF, 0xB8, 0x1D, 0xDC, 0xFF, 0x7C, 0xC0,
		0x78, 0x07, 0xFF, 0xFF, 0xFF, 0xFF, 0xFF, 0xFF, 0xFF, 0xFF, 0xFF, 0xFF, 0xF8, 0xE7, 0xCC, 0x7F,
		0xCE, 0x1C, 0xCF, 0xB9, 0xCC, 0xD8, 0xFF, 0x7C, 0xC7, 0x39, 0xC7, 0xFF, 0xFF, 0xFF, 0xFF, 0xFF,
		0xFF, 0xFF, 0xFF, 0xFF, 0xFF, 0xFD, 0xE7, 0xCC, 0xFF, 0xCF, 0x3C, 0xCF, 0xB9, 0xFC, 0xC9, 0xFF,
		0x7C, 0xCF, 0x33, 0xE7, 0xFF, 0xFF, 0xFF, 0xFF, 0xFF, 0xFF, 0xFF, 0xFF, 0xFF, 0xFF, 0xFD, 0xE7,
		0xCC, 0xFF, 0xDF, 0x3C, 0xCF, 0xB8, 0x7C, 0xC3, 0xFF, 0x7C, 0xCF, 0x33, 0xE7, 0xFF, 0xFF, 0xFF,
		0xFF, 0xFF, 0xFF, 0xFF, 0xFF, 0xFF, 0xFF, 0xFD, 0xE7, 0xCC, 0xFF, 0xDF, 0x3C, 0xCF, 0xBC, 0x1C,
		0xC3, 0xFF, 0x7C, 0xCF, 0x33, 0xE7, 0xFF, 0xFF, 0xFF, 0xFF, 0xFF, 0xFF, 0xFF, 0xFF, 0xFF, 0xFF,
		0xFD, 0xE7, 0xCC, 0xFF, 0xDF, 0x3C, 0xCF, 0xBF, 0x8C, 0xD9, 0xFF, 0x7C, 0xCF, 0x33, 0xE7, 0xFF,
		0xFF, 0xFF, 0xFF, 0xFF, 0xFF, 0xFF, 0xFF, 0xFF, 0xFF, 0xFD, 0xE7, 0x8C, 0xFF, 0xDF, 0x3C, 0xCF,
		0x3F, 0xCC, 0xD8, 0xFF, 0x3C, 0xCF, 0x33, 0xE7, 0xFF, 0xFF, 0xFF, 0xFF, 0xFF, 0xFF, 0xFF, 0xFF,
		0xFF, 0xFF, 0xFD, 0xF3, 0x8C, 0xFF, 0xDF, 0x3C, 0xE6, 0x39, 0xCC, 0xDC, 0xFF, 0x18, 0xCF, 0x39,
		0xC7, 0xFF, 0xFF, 0xFF, 0xFF, 0xFF, 0xFF, 0xFF, 0xFF, 0xFF, 0xFF, 0xFD, 0xF8, 0x5D, 0xFF, 0xDF,
		0x3E, 0xE1, 0x38, 0x1D, 0xDE, 0x7F, 0x84, 0xDF, 0xBC, 0x27, 0xFF, 0xFF, 0xFF, 0xFF, 0xFF, 0xFF,
		0xFF, 0xFF, 0xFF, 0xFF, 0xFF, 0xFF, 0xFF, 0xFF, 0xFF, 0xFF, 0xFF, 0xFF, 0xFF, 0xFF, 0xFF, 0xFF,
		0xFF, 0xFF, 0xFF, 0xFF, 0xFF, 0xFF, 0xFF, 0xFF, 0xFF, 0xFF, 0xFF, 0xFF, 0xFF, 0xFF, 0xFF, 0xFF,
		0xFF, 0xFF, 0xFF, 0xFF, 0xFF, 0xFF, 0xFF, 0xFF, 0xFF, 0xFF, 0xFF, 0xFF, 0xFF, 0xFF, 0xFF, 0xFF,
		0xFF, 0xFF, 0xFF, 0xFF, 0xFF, 0xFF, 0xFF, 0xFF, 0xFF, 0xFF, 0xFF, 0xFF, 0xFF, 0xFF, 0xFF, 0xFF,
		0xFF, 0xFF, 0xFF, 0xFF, 0xFF, 0xFF, 0xFF, 0xFF, 0xFF, 0xFF, 0xFF, 0xFF, 0xFF, 0xFF, 0xFF, 0xFF,
		0xFF, 0xFF, 0xFF, 0xFF, 0xFF, 0xFF, 0xFF, 0xFF, 0xFF, 0xFF, 0xFF, 0xFF, 0xFF, 0xFF, 0xFF, 0xFF,
		0xFF, 0xFF, 0xFF, 0xFF, 0xFF, 0xFF, 0xFF, 0xFF, 0xFF, 0xFF, 0xFF, 0xFF, 0xFF, 0xFF, 0xFF, 0xFF,
		0xFF, 0xFF, 0xFF, 0xFF, 0xFF, 0xFF, 0xFF, 0xFF, 0xFF, 0xFF, 0xFF, 0xFF, 0xFF, 0xFF, 0xFF, 0xFF,
		0xFF, 0xFF, 0xF7, 0xFF, 0xFF, 0xFF, 0xFF, 0xFF, 0xDD, 0xFF, 0xFF, 0xFF, 0xFB, 0xFF, 0xFF, 0xFF,
		0xFF, 0xFF, 0xFF, 0xFF, 0xFF, 0xFF, 0xFF, 0xFF, 0xFF, 0xFF, 0xFF, 0xF3, 0xFF, 0xFF, 0xFF, 0xFF,
		0xFF, 0xDD, 0xFF, 0xFF, 0xFF, 0xFB, 0xFF, 0xFF, 0xFF, 0xFF, 0xFF, 0xFF, 0xFF, 0xFF, 0xFF, 0xFF,
		0xFF, 0xFF, 0xFF, 0xFF, 0xF3, 0xFF, 0xFF, 0xFF, 0xCF, 0xFF, 0xDD, 0xFF, 0xFF, 0xFF, 0xFB, 0xFF,
		0xFF, 0xFF, 0xFF, 0xFF, 0xFF, 0xFF, 0xFF, 0xFF, 0xFF, 0xFF, 0xFF, 0xFF, 0xFF, 0xF3, 0xFF, 0xFF,
		0xFF, 0xCF, 0xFF, 0xDD, 0xFF, 0xFF, 0xFF, 0xFB, 0xFF, 0xFF, 0xFF, 0xFF, 0xFF, 0xFF, 0xFF, 0xFF,
		0xFF, 0xFF, 0xFF, 0xFF, 0xFF, 0xFE, 0x23, 0x83, 0xFB, 0xC3, 0x87, 0xC3, 0xDD, 0xE1, 0xFE, 0x3F,
		0x13, 0xE1, 0xFF, 0xFF, 0xFF, 0xFF, 0xFF, 0xFF, 0xFF, 0xFF, 0xFF, 0xFF, 0xFF, 0xFF, 0xFC, 0xC3,
		0x11, 0x83, 0x11, 0x87, 0x11, 0xDD, 0xC4, 0x61, 0x1E, 0x63, 0x8C, 0xFF, 0xFF, 0xFF, 0xFF, 0xFF,
		0xFF, 0xFF, 0xFF, 0xFF, 0xFF, 0xFF, 0xFF, 0xF9, 0xE3, 0x79, 0x8F, 0x39, 0xCF, 0x3D, 0xDD, 0x9E,
		0x63, 0x9C, 0xF3, 0x9E, 0x7F, 0xFF, 0xFF, 0xFF, 0xFF, 0xFF, 0xFF, 0xFF, 0xFF, 0xFF, 0xFF, 0xFF,
		0xF9, 0xF3, 0xF9, 0x9F, 0x3F, 0xCE, 0x7C, 0xDD, 0x9F, 0x67, 0xCC, 0xFB, 0x3E, 0x7F, 0xFF, 0xFF,
		0xFF, 0xFF, 0xFF, 0xFF, 0xFF, 0xFF, 0xFF, 0xFF, 0xFF, 0xFB, 0xF3, 0x81, 0x9F, 0x87, 0xCE, 0x00,
		0xDD, 0x80, 0x67, 0xCD, 0xFB, 0x00, 0x7F, 0xFF, 0xFF, 0xFF, 0xFF, 0xFF, 0xFF, 0xFF, 0xFF, 0xFF,
		0xFF, 0xFF, 0xFB, 0xF3, 0x39, 0x9F, 0xE1, 0xCE, 0x7F, 0xDD, 0x9F, 0xE7, 0xCD, 0xFB, 0x3F, 0xFF,
		0xFF, 0xFF, 0xFF, 0xFF, 0xFF, 0xFF, 0xFF, 0xFF, 0xFF, 0xFF, 0xFF, 0xF9, 0xF6, 0x7D, 0x9F, 0xF9,
		0xCE, 0x7F, 0xDD, 0x9F, 0xE7, 0xCC, 0xFB, 0x3F, 0xFF, 0xFF, 0xFF, 0xFF, 0xFF, 0xFF, 0xFF, 0xFF,
		0xFF, 0xFF, 0xFF, 0xFF, 0xF9, 0xE6, 0x79, 0x9F, 0x39, 0xCF, 0x3D, 0xDD, 0x9E, 0x67, 0xCC, 0xF3,
		0x9E, 0x7F, 0xFF, 0xFF, 0xFF, 0xFF, 0xFF, 0xFF, 0xFF, 0xFF, 0xFF, 0xFF, 0xFF, 0xFC, 0xC3, 0x31,
		0x9F, 0x11, 0xC7, 0x11, 0xDD, 0xC4, 0x67, 0xCE, 0x63, 0x8C, 0xFF, 0xFF, 0xFF, 0xFF, 0xFF, 0xFF,
		0xFF, 0xFF, 0xFF, 0xFF, 0xFF, 0xFF, 0xFE, 0x37, 0x8D, 0xDF, 0x83, 0xE3, 0x83, 0xDD, 0xE0, 0xF7,
		0xDF, 0x1B, 0xC1, 0xFF, 0xFF, 0xFF, 0xFF, 0xFF, 0xFF, 0xFF, 0xFF, 0xFF, 0xFF, 0xFF, 0xFF, 0xFF,
		0xFF, 0xFF, 0xFF, 0xFF, 0xFF, 0xFF, 0xFF, 0xFF, 0xFF, 0xFF, 0xFF, 0xFF, 0xFF, 0xFF, 0xFF, 0xFF,
		0xFF, 0xFF, 0xFF, 0xFF, 0xFF, 0xFF, 0xFF, 0xFF, 0xFF, 0xFF, 0xFF, 0xFF, 0xFF, 0xFF, 0xFF, 0xFF,
		0xFF, 0xFF, 0xFF, 0xFF, 0xFF, 0xFF, 0xFF, 0xFF, 0xFF, 0xFF, 0xFF, 0xFF, 0xFF, 0xFF, 0xFF, 0xFF,
		0xFF, 0xFF, 0xFF, 0xFF, 0xFF, 0xFF, 0xFF, 0xFF, 0xFF, 0xFF, 0xFF, 0xFF, 0xFF, 0xFF, 0xFF, 0xFF,
		0xFF, 0xFF, 0xFF, 0xFF, 0xFF, 0xFF, 0xFF, 0xFF, 0xFF, 0xFF, 0xFF, 0xFF, 0xFF, 0xFF, 0xFF, 0xFF,
		0xFF, 0xFF, 0xFF, 0xFF, 0xFF, 0xFF, 0xFF, 0xFF, 0xFF, 0xFF, 0xFF, 0xFF, 0xFF, 0xFF, 0xFF, 0xFF,
		0xFF, 0xFF, 0xFF, 0xFF, 0xFF, 0xFF, 0xFF, 0xFF, 0xFF, 0xFF, 0xFF, 0xFF, 0xFF, 0xFF, 0xFF, 0xFF,
		0xFF, 0xFF, 0xFF, 0xFF, 0xFF, 0xFF, 0xFF, 0xFF, 0xFF, 0xFF, 0xFF, 0xFF, 0xF9, 0xFF, 0xFF, 0xFF,
		0xFF, 0xFF, 0xFF, 0xFF, 0xFE, 0x7F, 0xFF, 0xFF, 0xFF, 0xFF, 0xFF, 0xFF, 0xFF, 0xFF, 0xFF, 0xFF,
		0xFF, 0xFF, 0xFF, 0xFF, 0xFF, 0xF9, 0xFF, 0xFF, 0xFF, 0xFF, 0xFF, 0xFF, 0xFF, 0xFF, 0x7F, 0xFF,
		0xFF, 0xFF, 0xFF, 0xFF, 0xFF, 0xFF, 0xFF, 0xFF, 0xFF, 0xFF, 0xFF, 0xFF, 0xFF, 0xFF, 0xF9, 0xFF,
		0xFF, 0xFF, 0xFF, 0xF9, 0xFF, 0xFF, 0xFF, 0xFF, 0xFF, 0xFF, 0xFF, 0xFF, 0xFF, 0xFF, 0xFF, 0xFF,
		0xFF, 0xFF, 0xFF, 0xFF, 0xFF, 0xFF, 0xFF, 0xF9, 0xFF, 0xFF, 0xFF, 0xFF, 0xF8, 0xFF, 0xFF, 0xFF,
		0xFF, 0xFF, 0xFF, 0xFF, 0xFF, 0xFF, 0xFF, 0xFF, 0xFF, 0xFF, 0xFF, 0xFF, 0xFF, 0xFF, 0xFF, 0xFF,
		0xF9, 0xCC, 0xFB, 0x90, 0xF0, 0x70, 0x7E, 0xF9, 0xF7, 0x78, 0x38, 0x0F, 0xFF, 0xFF, 0xFF, 0xFF,
		0xFF, 0xFF, 0xFF, 0xFF, 0xFF, 0xFF, 0xFF, 0xFF, 0xFF, 0xF9, 0x9C, 0xFB, 0x8C, 0x67, 0x39, 0xFE,
		0x70, 0xE7, 0x73, 0x98, 0xC7, 0xFF, 0xFF, 0xFF, 0xFF, 0xFF, 0xFF, 0xFF, 0xFF, 0xFF, 0xFF, 0xFF,
		0xFF, 0xFF, 0xF9, 0x3C, 0xFB, 0x9E, 0x67, 0xF9, 0xFE, 0x70, 0xE7, 0x67, 0x98, 0xE7, 0xFF, 0xFF,
		0xFF, 0xFF, 0xFF, 0xFF, 0xFF, 0xFF, 0xFF, 0xFF, 0xFF, 0xFF, 0xFF, 0xF8, 0x7C, 0xFB, 0xBE, 0x63,
		0xF9, 0xFE, 0x76, 0xEF, 0x67, 0x99, 0xF7, 0xFF, 0xFF, 0xFF, 0xFF, 0xFF, 0xFF, 0xFF, 0xFF, 0xFF,
		0xFF, 0xFF, 0xFF, 0xFF, 0xF8, 0x7C, 0xFB, 0xBE, 0x70, 0x79, 0xFF, 0x66, 0x4F, 0x60, 0x19, 0xF7,
		0xFF, 0xFF, 0xFF, 0xFF, 0xFF, 0xFF, 0xFF, 0xFF, 0xFF, 0xFF, 0xFF, 0xFF, 0xFF, 0xF8, 0x3C, 0xFB,
		0xBE, 0x7E, 0x39, 0xFF, 0x26, 0x4F, 0x67, 0xF9, 0xF7, 0xFF, 0xFF, 0xFF, 0xFF, 0xFF, 0xFF, 0xFF,
		0xFF, 0xFF, 0xFF, 0xFF, 0xFF, 0xFF, 0xF9, 0x9C, 0xF3, 0xBE, 0x7F, 0x39, 0xFF, 0x0E, 0x1F, 0x67,
		0xF9, 0xF7, 0xFF, 0xFF, 0xFF, 0xFF, 0xFF, 0xFF, 0xFF, 0xFF, 0xFF, 0xFF, 0xFF, 0xFF, 0xFF, 0xF9,
		0x8C, 0x73, 0xBE, 0x67, 0x39, 0xFF, 0x8F, 0x1F, 0x63, 0x99, 0xF7, 0xFF, 0xFF, 0xFF, 0xFF, 0xFF,
		0xFF, 0xFF, 0xFF, 0xFF, 0xFF, 0xFF, 0xFF, 0xFF, 0xF9, 0xCE, 0x03, 0xBE, 0x60, 0x38, 0x7F, 0x8F,
		0x3F, 0x70, 0x19, 0xF7, 0xFF, 0xFF, 0xFF, 0xFF, 0xFF, 0xFF, 0xFF, 0xFF, 0xFF, 0xFF, 0xFF, 0xFF,
		0xFF, 0xFF, 0xEF, 0x9F, 0xFF, 0xF0, 0xFC, 0x7F, 0xDF, 0xFF, 0xF8, 0x7F, 0xFF, 0xFF, 0xFF, 0xFF,
		0xFF, 0xFF, 0xFF, 0xFF, 0xFF, 0xFF, 0xFF, 0xFF, 0xFF, 0xFF, 0xFF, 0xFF, 0xFF, 0xFF, 0xFF, 0xFF,
		0xFF, 0xFF, 0xFF, 0xFF, 0xFF, 0xFF, 0xFF, 0xFF, 0xFF, 0xFF, 0xFF, 0xFF, 0xFF, 0xFF, 0xFF, 0xFF,
		0xFF, 0xFF, 0xFF, 0xFF, 0xFF, 0xFF, 0xFF, 0xFF, 0xFF, 0xFF, 0xFF, 0xFF, 0xFF, 0xFF, 0xFF, 0xFF,
		0xFF, 0xFF, 0xFF, 0xFF, 0xFF, 0xFF, 0xFF, 0xFF, 0xFF, 0xFF, 0xFF, 0xFF, 0xFF, 0xFF, 0xFF, 0xFF,
		0xFF, 0xFF, 0xFF, 0xFF, 0xFF, 0xFF, 0xFF, 0xFF, 0xFF, 0xFF, 0xFF, 0xFF, 0xFF, 0xFF, 0xFF, 0xFF,
		0xFF, 0xFF, 0xFF, 0xFF, 0xFF, 0xFF, 0xFF, 0xFF, 0xFF, 0xFF, 0xFF, 0xFF, 0xFF, 0xFF, 0xFF, 0xFF,
		0xFF, 0xFF, 0xFF, 0xFF, 0xFF, 0xFF, 0xFF, 0xFF, 0xFF, 0xFF, 0xFF, 0xFF, 0xFF, 0xFF, 0xFF, 0xFF,
		0xFF, 0xFF, 0xFF, 0xFF, 0xFF, 0xFF, 0xFF, 0xFF, 0xFF, 0xFF, 0xFF, 0xFF, 0xFF, 0xFF, 0xFF, 0xFF,
		0xFF, 0xFF, 0xFF, 0xFF, 0xFF, 0xFF, 0xFF, 0xFF, 0xFF, 0xFF, 0xFF, 0xFF, 0xFF, 0xFF, 0xFF, 0xFF,
		0xFF, 0xFF, 0xFF, 0xFF, 0xFF, 0xFF, 0xFF, 0xFF, 0xFF, 0xFF, 0xFF, 0xFF, 0xFF, 0xFF, 0xFF, 0xFF,
		0xFF, 0xFF, 0xFF, 0xFF, 0xFF, 0xFF, 0xFF, 0xFF, 0xFF, 0xFF, 0xFF, 0xFF, 0xFF, 0xFF, 0xFF, 0xFF,
		0xFF, 0xFF, 0xFF, 0xFF, 0xFF, 0xFF, 0xFF, 0xFF, 0xFF, 0xFF, 0xFF, 0xFF, 0xFF, 0xFF, 0xFF, 0xFF,
		0xFF, 0xFF, 0xFF, 0xFF, 0xFF, 0xFF, 0xFF, 0xFF, 0xFF, 0xFF, 0xFF, 0xFF, 0xFF, 0xFF, 0xFF, 0xFF,
		0xFF, 0xFF, 0xFF, 0xFF, 0xFF, 0xFF, 0xFF, 0xFF, 0xFF, 0xFF, 0xFF, 0xFF, 0xFF, 0xFF, 0xFF, 0xFF,
		0xFF, 0xFF, 0xFF, 0xFF, 0xFF, 0xFF, 0xFF, 0xFF, 0xFF, 0xFF, 0xFF, 0xFF, 0xFF, 0xFF, 0xFF, 0xFF,
		0xFF, 0xFF, 0xFF, 0xFF, 0xFF, 0xFF, 0xFF, 0xFF, 0xFF, 0xFF, 0xFF, 0xFF, 0xFF, 0xFF, 0xFF, 0xFF,
		0xFF, 0xFF, 0xFF, 0xFF, 0xFF, 0xFF, 0xFF, 0xFF, 0xFF, 0xFF, 0xFF, 0xFF, 0xFF, 0xFF, 0xFF, 0xFF,
		0xFF, 0xFF, 0xFF, 0xFF, 0xFF, 0xFF, 0xFF, 0xFF, 0xFF, 0xFF, 0xFF, 0xFF, 0xFF, 0xFF, 0xFF, 0xFF,
		0xFF, 0xFF, 0xFF, 0xFF, 0xFF, 0xFF, 0xFF, 0xFF, 0xFF, 0xFF, 0xFF, 0xFF, 0xFF, 0xFF, 0xFF, 0xFF,
		0xFF, 0xFF, 0xFF, 0xFF, 0xFF, 0xFF, 0xFF, 0xFF, 0xFF, 0xFF, 0xFF, 0xFF, 0xFF, 0xFF, 0xFF, 0xFF,
		0xFF, 0xFF, 0xFF, 0xFF, 0xFF, 0xFF, 0xFF, 0xFF, 0xFF, 0xFF, 0xFF, 0xFF, 0xFF, 0xFF, 0xFF, 0xFF,
		0xFF, 0xFF, 0xFF, 0xFF, 0xFF, 0xFF, 0xFF, 0xFF, 0xFF, 0xFF, 0xFF, 0xFF, 0xFF, 0xFF, 0xFF, 0xFF,
		0xFF, 0xFF, 0xFF, 0xFF, 0xFF, 0xFF, 0xFF, 0xFF, 0xFF, 0xFF, 0xFF, 0xFF, 0xFF, 0xFF, 0xFF, 0xFF,
		0xFF, 0xFF, 0xFF, 0xFF, 0xFF, 0xFF, 0xFF, 0xFF, 0xFF, 0xFF, 0xFF, 0xFF, 0xFF, 0xFF, 0xFF, 0xFF,
		0xFF, 0xFF, 0xFF, 0xFF, 0xFF, 0xFF, 0xFF, 0xFF, 0xFF, 0xFF, 0xFF, 0xFF, 0xFF, 0xFF, 0xFF, 0xFF,
		0xFF, 0xFF, 0xFF, 0xFF, 0xFF, 0xFF, 0xFF, 0xFF, 0xFF, 0xFF, 0xFF, 0xFF, 0xFF, 0xFF, 0xFF, 0xFF,
		0xFF, 0xFF, 0xFF, 0xFF, 0xFF, 0xFF, 0xFF, 0xFF, 0xFF, 0xFF, 0xFF, 0xFF, 0xFF, 0xFF, 0xFF, 0xFF,
		0xFF, 0xFF, 0xFF, 0xFF, 0xFF, 0xFF, 0xFF, 0xFF, 0xFF, 0xFF, 0xFF, 0xFF, 0xFF, 0xFF, 0xFF, 0xFF,
		0xFF, 0xFF, 0xFF, 0xFF, 0xFF, 0xFF, 0xFF, 0xFF, 0xFF, 0xFF, 0xFF, 0xFF, 0xFF, 0xFF, 0xFF, 0xFF,
		0xFF, 0xFF, 0xFF, 0xFF, 0xFF, 0xFF, 0xFF, 0xFF, 0xFF, 0xFF, 0xFF, 0xFF, 0xFF, 0xFF, 0xFF, 0xFF,
		0xFF, 0xFF, 0xFF, 0xFF, 0xFF, 0xFF, 0xFF, 0xFF, 0xFF, 0xFF, 0xFF, 0xFF, 0xFF, 0xFF, 0xFF, 0xFF,
		0xFF, 0xFF, 0xFF, 0xFF, 0xFF, 0xFF, 0xFF, 0xFF, 0xFF, 0xFF, 0xFF, 0xFF, 0xFF, 0xFF, 0xFF, 0xFF,
		0xFF, 0xFF, 0xFF, 0xFF, 0xFF, 0xFF, 0xFF, 0xFF, 0xFF, 0xFF, 0xFF, 0xFF, 0xFF, 0xFF, 0xFF, 0xFF,
		0xFF, 0xFF, 0xFF, 0xFF, 0xFF, 0xFF, 0xFF, 0xFF, 0xFF, 0xFF, 0xFF, 0xFF, 0xFF, 0xFF, 0xFF, 0xFF,
		0xFF, 0xFF, 0xFF, 0xFF, 0xFF, 0xFF, 0xFF, 0xFF, 0xFF, 0xFF, 0xFF, 0xFF, 0xFF, 0xFF, 0xFF, 0xFF,
		0xFF, 0xFF, 0xFF, 0xFF, 0xFF, 0xFF, 0xFF, 0xFF, 0xFF, 0xFF, 0xFF, 0xFF, 0xFF, 0xFF, 0xFF, 0xFF,
		0xFF, 0xFF, 0xFF, 0xFF, 0xFF, 0xFF, 0xFF, 0xFF, 0xFF, 0xFF, 0xFF, 0xFF, 0xFF, 0xFF, 0xFF, 0xFF,
		0xFF, 0xFF, 0xFF, 0xFF, 0xFF, 0xFF, 0xFF, 0xFF,
};

uint32_t WhileLoopCounter = 0x00;
/* USER CODE END 0 */

int main(void)
{

  /* MCU Configuration--------------------------------------------------------*/

  /* Reset of all peripherals, Initializes the Flash interface and the Systick. */
  HAL_Init();

  /* Configure the system clock */
  SystemClock_Config();

  /* Initialize all configured peripherals */
  MX_GPIO_Init();
  MX_DMA_Init();
  MX_SPI1_Init();
  /* USER CODE BEGIN 2 */

  EPD_init_PinDC(&Display, GPIOA, GPIO_PIN_1);
  EPD_init_PinCS(&Display, GPIOA, GPIO_PIN_2);
  EPD_init_PinRST(&Display, GPIOA, GPIO_PIN_3);
  EPD_init_PinBUSY(&Display, GPIOA, GPIO_PIN_4);
  EPD_init_SPI(&Display, &hspi1);
  EPD_init(&Display);

  EPD_set_FullRefreshMode(&Display);

  EPD_set_BitmapInvert(&Display);
  EPD_draw_Bitmap(&Display, mdw_Logo, 200, 200);
  EPD_display_Frame(&Display);

  for(int i = 0; i < 1; i++)
  {
    EPD_set_DrawColor(&Display, EPD_COLOR_WHITE);
    EPD_clear(&Display);
    EPD_display_Frame(&Display);

		HAL_Delay(1000);

		EPD_set_DrawColor(&Display, EPD_COLOR_BLACK);
		EPD_clear(&Display);
		EPD_display_Frame(&Display);

		HAL_Delay(1000);
  }

  EPD_set_DrawColor(&Display, EPD_COLOR_WHITE);
  EPD_set_Font(&Display, EBGaramond08_28pt);
  EPD_set_PixelStartPosition(&Display, 10, 10);
  char* txt1 = "Success!";
  EPD_write_String(&Display, txt1, strlen(txt1));

  EPD_set_PartRefreshMode(&Display);
  EPD_display_Frame(&Display);

  /* USER CODE END 2 */

  /* Infinite loop */
  while (1)
  {

  }
}

void SystemClock_Config(void)
{
  RCC_OscInitTypeDef RCC_OscInitStruct = {0};
  RCC_ClkInitTypeDef RCC_ClkInitStruct = {0};

  /** Initializes the RCC Oscillators according to the specified parameters
  * in the RCC_OscInitTypeDef structure.
  */
  RCC_OscInitStruct.OscillatorType = RCC_OSCILLATORTYPE_HSE;
  RCC_OscInitStruct.HSEState = RCC_HSE_ON;
  RCC_OscInitStruct.HSEPredivValue = RCC_HSE_PREDIV_DIV1;
  RCC_OscInitStruct.HSIState = RCC_HSI_ON;
  RCC_OscInitStruct.PLL.PLLState = RCC_PLL_ON;
  RCC_OscInitStruct.PLL.PLLSource = RCC_PLLSOURCE_HSE;
  RCC_OscInitStruct.PLL.PLLMUL = RCC_PLL_MUL9;
  if (HAL_RCC_OscConfig(&RCC_OscInitStruct) != HAL_OK)
  {
    Error_Handler();
  }

  /** Initializes the CPU, AHB and APB buses clocks
  */
  RCC_ClkInitStruct.ClockType = RCC_CLOCKTYPE_HCLK|RCC_CLOCKTYPE_SYSCLK
                              |RCC_CLOCKTYPE_PCLK1|RCC_CLOCKTYPE_PCLK2;
  RCC_ClkInitStruct.SYSCLKSource = RCC_SYSCLKSOURCE_PLLCLK;
  RCC_ClkInitStruct.AHBCLKDivider = RCC_SYSCLK_DIV1;
  RCC_ClkInitStruct.APB1CLKDivider = RCC_HCLK_DIV2;
  RCC_ClkInitStruct.APB2CLKDivider = RCC_HCLK_DIV1;

  if (HAL_RCC_ClockConfig(&RCC_ClkInitStruct, FLASH_LATENCY_2) != HAL_OK)
  {
    Error_Handler();
  }
}

static void MX_SPI1_Init(void)
{

  /* SPI1 parameter configuration*/
  hspi1.Instance = SPI1;
  hspi1.Init.Mode = SPI_MODE_MASTER;
  hspi1.Init.Direction = SPI_DIRECTION_2LINES;
  hspi1.Init.DataSize = SPI_DATASIZE_8BIT;
  hspi1.Init.CLKPolarity = SPI_POLARITY_HIGH;
  hspi1.Init.CLKPhase = SPI_PHASE_2EDGE;
  hspi1.Init.NSS = SPI_NSS_SOFT;
  hspi1.Init.BaudRatePrescaler = SPI_BAUDRATEPRESCALER_256;
  hspi1.Init.FirstBit = SPI_FIRSTBIT_MSB;
  hspi1.Init.TIMode = SPI_TIMODE_DISABLE;
  hspi1.Init.CRCCalculation = SPI_CRCCALCULATION_DISABLE;
  hspi1.Init.CRCPolynomial = 10;
  if (HAL_SPI_Init(&hspi1) != HAL_OK)
  {
    Error_Handler();
  }

}

static void MX_DMA_Init(void)
{

  /* DMA controller clock enable */
  __HAL_RCC_DMA1_CLK_ENABLE();

  /* DMA interrupt init */
  /* DMA1_Channel3_IRQn interrupt configuration */
  HAL_NVIC_SetPriority(DMA1_Channel3_IRQn, 0, 0);
  HAL_NVIC_EnableIRQ(DMA1_Channel3_IRQn);

}

static void MX_GPIO_Init(void)
{
  GPIO_InitTypeDef GPIO_InitStruct = {0};

  /* GPIO Ports Clock Enable */
  __HAL_RCC_GPIOD_CLK_ENABLE();
  __HAL_RCC_GPIOA_CLK_ENABLE();

  /*Configure GPIO pin Output Level */
  HAL_GPIO_WritePin(GPIOA, EPD_DC_Pin|EPD_CS_Pin|EPD_RST_Pin, GPIO_PIN_RESET);

  /*Configure GPIO pins : EPD_DC_Pin EPD_CS_Pin EPD_RST_Pin */
  GPIO_InitStruct.Pin = EPD_DC_Pin|EPD_CS_Pin|EPD_RST_Pin;
  GPIO_InitStruct.Mode = GPIO_MODE_OUTPUT_PP;
  GPIO_InitStruct.Pull = GPIO_NOPULL;
  GPIO_InitStruct.Speed = GPIO_SPEED_FREQ_LOW;
  HAL_GPIO_Init(GPIOA, &GPIO_InitStruct);

  /*Configure GPIO pin : EPD_BSY_Pin */
  GPIO_InitStruct.Pin = EPD_BSY_Pin;
  GPIO_InitStruct.Mode = GPIO_MODE_INPUT;
  GPIO_InitStruct.Pull = GPIO_NOPULL;
  HAL_GPIO_Init(EPD_BSY_GPIO_Port, &GPIO_InitStruct);

}

/* USER CODE BEGIN 4 */
void HAL_SPI_TxCpltCallback(SPI_HandleTypeDef* hspi)
{
  EPD_manage_Interrupt(&Display, hspi);
}
/* USER CODE END 4 */

void Error_Handler(void)
{
  __disable_irq();
  while (1)
  {
  }
}
